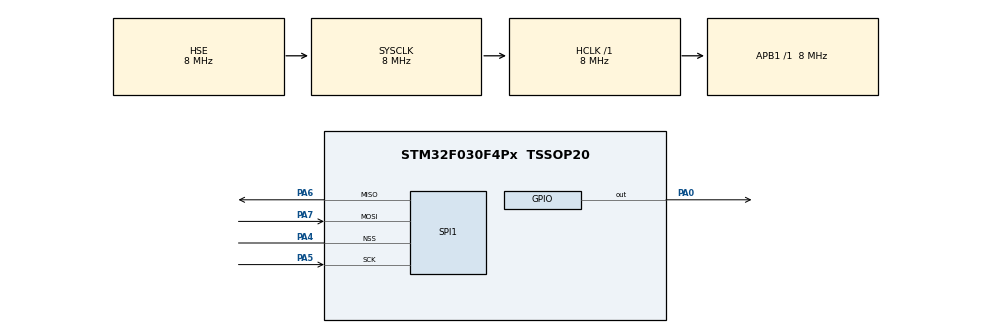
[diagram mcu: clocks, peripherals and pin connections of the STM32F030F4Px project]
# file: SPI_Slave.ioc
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Mcu.Family=STM32F0
Mcu.Name=STM32F030F4Px
Mcu.Package=TSSOP20
NVIC.SPI1_IRQn=true\:0\:0\:false
PA0.GPIO_PuPd=GPIO_NOPULL
PA0.GPIO_Speed=GPIO_SPEED_LOW
PA0.Signal=GPIO_Output
PA4.Mode=NSS_Signal_Hard
PA4.Signal=SPI1_NSS
PA5.Mode=Full_Duplex_Slave
PA5.Signal=SPI1_SCK
PA6.Mode=Full_Duplex_Slave
PA6.Signal=SPI1_MISO
PA7.Mode=Full_Duplex_Slave
PA7.Signal=SPI1_MOSI
PF0-OSC_IN.Mode=HSE-External-Oscillator
PF0-OSC_IN.Signal=RCC_OSC_IN
PF1-OSC_OUT.Mode=HSE-External-Oscillator
PF1-OSC_OUT.Signal=RCC_OSC_OUT
ProjectManager.TargetToolchain=EWARM
RCC.AHBFreq_Value=8000000
RCC.APB1Freq_Value=8000000
RCC.APB1TimFreq_Value=8000000
RCC.HCLKFreq_Value=8000000
RCC.HSIState=RCC_HSI_ON
RCC.PLLSourceVirtual=RCC_PLLSOURCE_HSE
RCC.SYSCLKFreq_VALUE=8000000
RCC.SYSCLKSource=RCC_SYSCLKSOURCE_HSE
SPI1.DataSize=SPI_DATASIZE_8BIT
SPI1.VirtualNSS=VM_NSSHARD
SPI1.VirtualType=VM_SLAVE
board=SPI_Slave

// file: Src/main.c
/**
  ******************************************************************************
  * File Name          : main.c
  * Description        : Main program body
  ******************************************************************************
  *
  * COPYRIGHT(c) 2016 STMicroelectronics
  *
  * Redistribution and use in source and binary forms, with or without modification,
  * are permitted provided that the following conditions are met:
  *   1. Redistributions of source code must retain the above copyright notice,
  *      this list of conditions and the following disclaimer.
  *   2. Redistributions in binary form must reproduce the above copyright notice,
  *      this list of conditions and the following disclaimer in the documentation
  *      and/or other materials provided with the distribution.
  *   3. Neither the name of STMicroelectronics nor the names of its contributors
  *      may be used to endorse or promote products derived from this software
  *      without specific prior written permission.
  *
  * THIS SOFTWARE IS PROVIDED BY THE COPYRIGHT HOLDERS AND CONTRIBUTORS "AS IS"
  * AND ANY EXPRESS OR IMPLIED WARRANTIES, INCLUDING, BUT NOT LIMITED TO, THE
  * IMPLIED WARRANTIES OF MERCHANTABILITY AND FITNESS FOR A PARTICULAR PURPOSE ARE
  * DISCLAIMED. IN NO EVENT SHALL THE COPYRIGHT HOLDER OR CONTRIBUTORS BE LIABLE
  * FOR ANY DIRECT, INDIRECT, INCIDENTAL, SPECIAL, EXEMPLARY, OR CONSEQUENTIAL
  * DAMAGES (INCLUDING, BUT NOT LIMITED TO, PROCUREMENT OF SUBSTITUTE GOODS OR
  * SERVICES; LOSS OF USE, DATA, OR PROFITS; OR BUSINESS INTERRUPTION) HOWEVER
  * CAUSED AND ON ANY THEORY OF LIABILITY, WHETHER IN CONTRACT, STRICT LIABILITY,
  * OR TORT (INCLUDING NEGLIGENCE OR OTHERWISE) ARISING IN ANY WAY OUT OF THE USE
  * OF THIS SOFTWARE, EVEN IF ADVISED OF THE POSSIBILITY OF SUCH DAMAGE.
  *
  ******************************************************************************
  */
#include "stm32f0xx_hal.h"

SPI_HandleTypeDef hspi1;

/* USER CODE BEGIN PV */
/* Private variables ---------------------------------------------------------*/

unsigned char d;

/* USER CODE END PV */

void SystemClock_Config(void);
static void MX_GPIO_Init(void);
static void MX_SPI1_Init(void);

/* USER CODE BEGIN PFP */
/* Private function prototypes -----------------------------------------------*/

/* USER CODE END PFP */

int main(void)
{

  /* MCU Configuration----------------------------------------------------------*/

  /* Reset of all peripherals, Initializes the Flash interface and the Systick. */
  HAL_Init();

  /* Configure the system clock */
  SystemClock_Config();

  /* Initialize all configured peripherals */
  MX_GPIO_Init();
  MX_SPI1_Init();

  /* USER CODE BEGIN 2 */

  HAL_SPI_Receive_IT(&hspi1, &d, 1);

  /* USER CODE END 2 */

  /* Infinite loop */
  /* USER CODE BEGIN WHILE */
  while (1)
  {

    if(hspi1.RxXferCount==0)
      HAL_SPI_Receive_IT(&hspi1, &d, 1);

    if(d=='A')
      HAL_GPIO_WritePin(GPIOA, GPIO_PIN_0, GPIO_PIN_SET);
    else
      HAL_GPIO_WritePin(GPIOA, GPIO_PIN_0, GPIO_PIN_RESET);

  /* USER CODE END WHILE */

  }

}

/** System Clock Configuration
*/
void SystemClock_Config(void)
{

  RCC_OscInitTypeDef RCC_OscInitStruct;
  RCC_ClkInitTypeDef RCC_ClkInitStruct;

  RCC_OscInitStruct.OscillatorType = RCC_OSCILLATORTYPE_HSE;
  RCC_OscInitStruct.HSEState = RCC_HSE_ON;
  RCC_OscInitStruct.PLL.PLLState = RCC_PLL_NONE;
  HAL_RCC_OscConfig(&RCC_OscInitStruct);

  RCC_ClkInitStruct.ClockType = RCC_CLOCKTYPE_SYSCLK;
  RCC_ClkInitStruct.SYSCLKSource = RCC_SYSCLKSOURCE_HSE;
  RCC_ClkInitStruct.AHBCLKDivider = RCC_SYSCLK_DIV1;
  RCC_ClkInitStruct.APB1CLKDivider = RCC_HCLK_DIV1;
  HAL_RCC_ClockConfig(&RCC_ClkInitStruct, FLASH_LATENCY_0);

  HAL_SYSTICK_Config(HAL_RCC_GetHCLKFreq()/1000);

  HAL_SYSTICK_CLKSourceConfig(SYSTICK_CLKSOURCE_HCLK);

  /* SysTick_IRQn interrupt configuration */
  HAL_NVIC_SetPriority(SysTick_IRQn, 0, 0);
}

/* SPI1 init function */
void MX_SPI1_Init(void)
{

  hspi1.Instance = SPI1;
  hspi1.Init.Mode = SPI_MODE_SLAVE;
  hspi1.Init.Direction = SPI_DIRECTION_2LINES;
  hspi1.Init.DataSize = SPI_DATASIZE_8BIT;
  hspi1.Init.CLKPolarity = SPI_POLARITY_LOW;
  hspi1.Init.CLKPhase = SPI_PHASE_1EDGE;
  hspi1.Init.NSS = SPI_NSS_HARD_INPUT;
  hspi1.Init.FirstBit = SPI_FIRSTBIT_MSB;
  hspi1.Init.TIMode = SPI_TIMODE_DISABLED;
  hspi1.Init.CRCCalculation = SPI_CRCCALCULATION_DISABLED;
  hspi1.Init.CRCPolynomial = 7;
  hspi1.Init.CRCLength = SPI_CRC_LENGTH_DATASIZE;
  hspi1.Init.NSSPMode = SPI_NSS_PULSE_DISABLED;
  HAL_SPI_Init(&hspi1);

}

/** Configure pins as
        * Analog
        * Input
        * Output
        * EVENT_OUT
        * EXTI
*/
void MX_GPIO_Init(void)
{

  GPIO_InitTypeDef GPIO_InitStruct;

  /* GPIO Ports Clock Enable */
  __GPIOF_CLK_ENABLE();
  __GPIOA_CLK_ENABLE();

  /*Configure GPIO pin : PA0 */
  GPIO_InitStruct.Pin = GPIO_PIN_0;
  GPIO_InitStruct.Mode = GPIO_MODE_OUTPUT_PP;
  GPIO_InitStruct.Pull = GPIO_NOPULL;
  GPIO_InitStruct.Speed = GPIO_SPEED_LOW;
  HAL_GPIO_Init(GPIOA, &GPIO_InitStruct);

}

/************************ (C) COPYRIGHT STMicroelectronics *****END OF FILE****/
